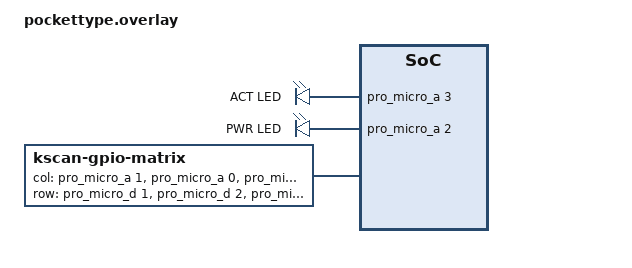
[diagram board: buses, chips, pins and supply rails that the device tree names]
/*
 * Copyright (c) 2020 The ZMK Contributors
 *
 * SPDX-License-Identifier: MIT
 */

#include <dt-bindings/zmk/matrix_transform.h>

/ {
	chosen {
		zmk,physical-layout = &layout_pockettype_posmap;
	};

	leds {
		compatible = "gpio-leds";
		actled: led_a {
			gpios = <&pro_micro_a 3 GPIO_ACTIVE_HIGH>;
			label = "ACT LED";
		};
		powerled: led_p {
			gpios = <&pro_micro_a 2 GPIO_ACTIVE_HIGH>;
			label = "PWR LED";
		};
	};

	kscan0: kscan {
		compatible = "zmk,kscan-gpio-matrix";
		label = "KSCAN";
		wakeup-source;

		diode-direction = "col2row";

		col-gpios
			= <&pro_micro_a 1 GPIO_ACTIVE_HIGH>
			, <&pro_micro_a 0 GPIO_ACTIVE_HIGH>
			, <&pro_micro_d 15 GPIO_ACTIVE_HIGH>
			, <&pro_micro_d 14 GPIO_ACTIVE_HIGH>
			, <&pro_micro_d 16 GPIO_ACTIVE_HIGH>
			, <&pro_micro_d 10 GPIO_ACTIVE_HIGH>
			, <&pro_micro_d 8 GPIO_ACTIVE_HIGH>
			, <&pro_micro_d 7 GPIO_ACTIVE_HIGH>
			, <&pro_micro_d 5 GPIO_ACTIVE_HIGH>
			, <&pro_micro_d 4 GPIO_ACTIVE_HIGH>
			, <&pro_micro_d 3 GPIO_ACTIVE_HIGH>
			, <&pro_micro_d 0 GPIO_ACTIVE_HIGH>
			;

		row-gpios
			= <&pro_micro_d 1 (GPIO_ACTIVE_HIGH | GPIO_PULL_DOWN)>
			, <&pro_micro_d 2 (GPIO_ACTIVE_HIGH | GPIO_PULL_DOWN)>
			, <&pro_micro_d 6 (GPIO_ACTIVE_HIGH | GPIO_PULL_DOWN)>
			, <&pro_micro_d 9 (GPIO_ACTIVE_HIGH | GPIO_PULL_DOWN)>
			;
	};

	physical_layout0 {
		compatible = "zmk,physical-layout";
		display-name = "PocketType 40%";
		
		keys = <
			/* Row 0 */
			RC(0,0)  100 100   0 0 0 0 0
			RC(0,1)  100 100 100 0 0 0 0
			RC(0,2)  100 100 200 0 0 0 0
			RC(0,3)  100 100 300 0 0 0 0
			RC(0,4)  100 100 400 0 0 0 0
			RC(0,5)  100 100 500 0 0 0 0
			RC(0,6)  100 100 600 0 0 0 0
			RC(0,7)  100 100 700 0 0 0 0
			RC(0,8)  100 100 800 0 0 0 0
			RC(0,9)  100 100 900 0 0 0 0
			RC(0,10) 100 100 1000 0 0 0 0
			RC(0,11) 100 100 1100 0 0 0 0
			/* Row 1 */
			RC(1,0)  100 100   0 100 0 0 0
			RC(1,1)  100 100 100 100 0 0 0
			RC(1,2)  100 100 200 100 0 0 0
			RC(1,3)  100 100 300 100 0 0 0
			RC(1,4)  100 100 400 100 0 0 0
			RC(1,5)  100 100 500 100 0 0 0
			RC(1,6)  100 100 600 100 0 0 0
			RC(1,7)  100 100 700 100 0 0 0
			RC(1,8)  100 100 800 100 0 0 0
			RC(1,9)  100 100 900 100 0 0 0
			RC(1,10) 100 100 1000 100 0 0 0
			RC(1,11) 100 100 1100 100 0 0 0
			/* Row 2 */
			RC(2,0)  100 100   0 200 0 0 0
			RC(2,1)  100 100 100 200 0 0 0
			RC(2,2)  100 100 200 200 0 0 0
			RC(2,3)  100 100 300 200 0 0 0
			RC(2,4)  100 100 400 200 0 0 0
			RC(2,5)  100 100 500 200 0 0 0
			RC(2,6)  100 100 600 200 0 0 0
			RC(2,7)  100 100 700 200 0 0 0
			RC(2,8)  100 100 800 200 0 0 0
			RC(2,9)  100 100 900 200 0 0 0
			RC(2,10) 100 100 1000 200 0 0 0
			RC(2,11) 100 100 1100 200 0 0 0
			/* Row 3 */
			RC(3,0)  100 100   0 300 0 0 0
			RC(3,1)  100 100 100 300 0 0 0
			RC(3,2)  100 100 200 300 0 0 0
			RC(3,3)  100 100 300 300 0 0 0
			RC(3,4)  100 100 400 300 0 0 0
			RC(3,5)  100 100 500 300 0 0 0
			RC(3,6)  100 100 600 300 0 0 0
			RC(3,7)  100 100 700 300 0 0 0
			RC(3,8)  100 100 800 300 0 0 0
			RC(3,9)  100 100 900 300 0 0 0
			RC(3,10) 100 100 1000 300 0 0 0
			RC(3,11) 100 100 1100 300 0 0 0
		>;
	};

	chosen {
		zmk,kscan = &kscan0;
		zmk,physical-layout = &physical_layout0;
	};
};
